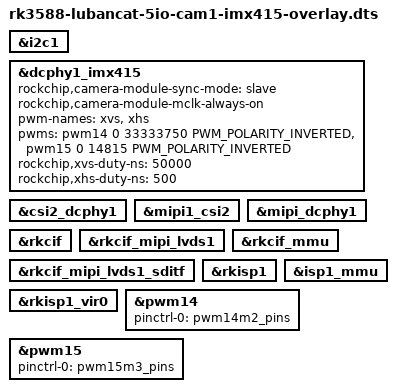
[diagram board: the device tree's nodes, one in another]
/dts-v1/;
/plugin/;

#include <dt-bindings/usb/pd.h>
#include <dt-bindings/gpio/gpio.h>
#include <dt-bindings/pwm/pwm.h>
#include <dt-bindings/pinctrl/rockchip.h>
#include <dt-bindings/input/rk-input.h>
#include <dt-bindings/display/drm_mipi_dsi.h>
#include <dt-bindings/display/rockchip_vop.h>
#include <dt-bindings/sensor-dev.h>

/ {
/* Link path: sensor->csi2_dphy1->mipi2_csi2->rkcif_mipi_lvds2--->rkcif_mipi_lvds2_sditf->rkisp0_vir2 */
/* IMX415 cam1 从模式：由 PWM XVS/XHS 触发，echo 1 > /sys/bus/i2c/devices/.../trigger 拍一帧 */
	fragment@0 {
		target = <&i2c1>;
		__overlay__ {
			status = "okay";
		};
	};

	fragment@1 {
		target = <&dcphy1_imx415>;
		__overlay__ {
			status = "okay";
			rockchip,camera-module-sync-mode = "slave";
			rockchip,camera-module-mclk-always-on;
			pwm-names = "xvs", "xhs";
			/* 4K@30: VMAX=2250 => XVS period ~= XHS period * 2250 */
			pwms = <&pwm14 0 33333750 PWM_POLARITY_INVERTED>,
			       <&pwm15 0 14815 PWM_POLARITY_INVERTED>;
			rockchip,xvs-duty-ns = <50000>;
			rockchip,xhs-duty-ns = <500>;
		};
	};

	fragment@2 {
		target = <&csi2_dcphy1>;

		__overlay__ {
			status = "okay";
		};
	};

	fragment@3 {
		target = <&mipi1_csi2>;

		__overlay__ {
			status = "okay";
		};
	};

	fragment@4 {
		target = <&mipi_dcphy1>;

		__overlay__ {
			status = "okay";
		};
	};

	fragment@5 {
		target = <&rkcif>;

		__overlay__ {
			status = "okay";
		};
	};

	fragment@6 {
		target = <&rkcif_mipi_lvds1>;

		__overlay__ {
			status = "okay";
		};
	};

	fragment@7 {
		target = <&rkcif_mipi_lvds1_sditf>;

		__overlay__ {
			status = "okay";
		};
	};

	fragment@8 {
		target = <&rkcif_mmu>;

		__overlay__ {
			status = "okay";
		};
	};

	fragment@9 {
		target = <&rkisp1>;

		__overlay__ {
			status = "okay";
		};
	};

	fragment@10 {
		target = <&isp1_mmu>;

		__overlay__ {
			status = "okay";
		};
	};

	fragment@11 {
		target = <&rkisp1_vir0>;

		__overlay__ {
			status = "okay";
		};
	};

	/* Enable PWMs for XVS/XHS trigger output (default: disabled in rk3588s.dtsi). */
	fragment@12 {
		target = <&pwm14>;

		__overlay__ {
			status = "okay";
			pinctrl-names = "active";
			pinctrl-0 = <&pwm14m2_pins>;
		};
	};

	fragment@13 {
		target = <&pwm15>;

		__overlay__ {
			status = "okay";
			pinctrl-names = "active";
			pinctrl-0 = <&pwm15m3_pins>;
		};
	};
};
